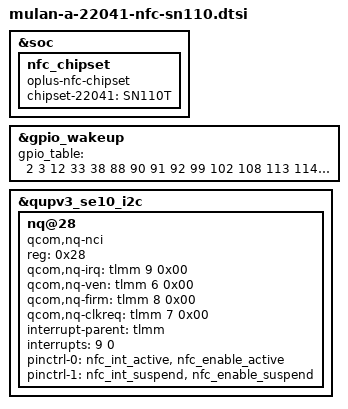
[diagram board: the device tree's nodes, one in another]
/**********************************************************************************
* Copyright (c)  2008-2020  Guangdong oplus Mobile Comm Corp., Ltd
* Description: oplus sn110 nfc dtsi
*
* Version: 1.0
* Date: 2022-03-19
* Author: HuangRuHong
*
* ------------------------------ Revision History: --------------------------------
* <version>           <date>                <author>                            <desc>
* Revision 1.0       2022-03-19            HuangRuHong           Created for SN110T nfc dtsi
***********************************************************************************/
&soc {
	//add for nfc_chipset
	nfc_chipset {
        compatible = "oplus-nfc-chipset";
	chipset-22041 = "SN110T";
	};
};

//add for disable wake-up function of NC-GPIO
&gpio_wakeup {
    gpio_table = <2 3 12 33 38 88 90 91 92 99 102 108 113 114 115 116
                  48 51 59 84 85 107 117 118 152 153 154 155>;
};

&qupv3_se10_i2c {
        status = "ok";
        #address-cells = <1>;
        #size-cells = <0>;
        nq@28 {
                compatible = "qcom,nq-nci";
                reg = <0x28>;
                qcom,nq-irq = <&tlmm 9 0x00>;
                qcom,nq-ven = <&tlmm 6 0x00>;
                qcom,nq-firm = <&tlmm 8 0x00>;
                qcom,nq-clkreq = <&tlmm 7 0x00>;
                interrupt-parent = <&tlmm>;
                interrupts = <9 0>;
                interrupt-names = "nfc_irq";
                pinctrl-names = "nfc_active", "nfc_suspend";
                pinctrl-0 = <&nfc_int_active &nfc_enable_active>;
                pinctrl-1 = <&nfc_int_suspend &nfc_enable_suspend>;
        };
};
